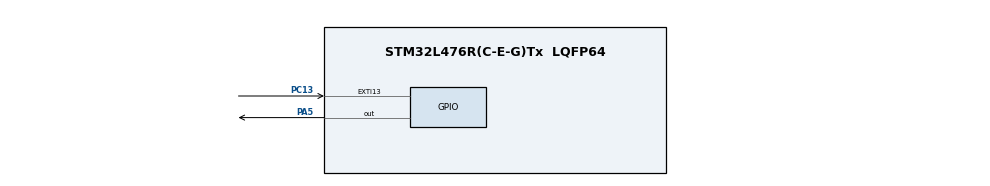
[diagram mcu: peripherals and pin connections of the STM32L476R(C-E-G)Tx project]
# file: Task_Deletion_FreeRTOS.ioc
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FREERTOS.Tasks01=defaultTask,24,128,StartDefaultTask,Default,NULL,Dynamic,NULL,NULL
Mcu.Family=STM32L4
Mcu.Name=STM32L476R(C-E-G)Tx
Mcu.Package=LQFP64
NVIC.EXTI15_10_IRQn=true\:5\:0\:false\:true\:true\:1\:true\:true\:true\:true
NVIC.PriorityGroup=NVIC_PRIORITYGROUP_4
PA5.Signal=GPIO_Output
PC13.Signal=GPXTI13
ProjectManager.HeapSize=0x200
ProjectManager.StackSize=0x400
ProjectManager.TargetToolchain=STM32CubeIDE
RCC.HSE_VALUE=8000000
RCC.HSI_VALUE=16000000
RCC.LSE_VALUE=32768
RCC.MSI_VALUE=4000000
RCC.VCOOutputFreq_Value=32000000
VP_FREERTOS_VS_CMSIS_V2.Mode=CMSIS_V2
board=custom

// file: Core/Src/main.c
/* USER CODE BEGIN Header */
/**
  ******************************************************************************
  * @file           : main.c
  * @brief          : Main program body
  ******************************************************************************
  * @attention
  *
  * Copyright (c) 2026 STMicroelectronics.
  * All rights reserved.
  *
  * This software is licensed under terms that can be found in the LICENSE file
  * in the root directory of this software component.
  * If no LICENSE file comes with this software, it is provided AS-IS.
  *
  ******************************************************************************
  */
/* USER CODE END Header */
#include "main.h"
#include "cmsis_os.h"

/* USER CODE BEGIN Includes */
#include <stdio.h>
#include "task.h"

/* USER CODE END Includes */

/* Definitions for defaultTask */

/* USER CODE BEGIN PV */
xTaskHandle Task1_Handle;
xTaskHandle Task2_Handle;
/* USER CODE END PV */

void SystemClock_Config(void);
static void MX_GPIO_Init(void);
void StartDefaultTask(void *argument);

static void MX_NVIC_Init(void);
/* USER CODE BEGIN PFP */
void Task1(void *argument);
void Task2(void *argument);

/* USER CODE END PFP */

int main(void)
{

  /* MCU Configuration--------------------------------------------------------*/

  /* Reset of all peripherals, Initializes the Flash interface and the Systick. */
  HAL_Init();

  /* Configure the system clock */
  SystemClock_Config();

  /* Initialize all configured peripherals */
  MX_GPIO_Init();

  /* Initialize interrupts */
  MX_NVIC_Init();

  /* Init scheduler */
  osKernelInitialize();

  /* Create the thread(s) */
  /* creation of defaultTask */
//  defaultTaskHandle = osThreadNew(StartDefaultTask, NULL, &defaultTask_attributes);

  xTaskCreate(Task2,"Task2",128,NULL,2,&Task1_Handle);
  xTaskCreate(Task1,"Task1",128,NULL,1,&Task2_Handle);

  /* Start scheduler */
//  osKernelStart();
  vTaskStartScheduler();
  /* We should never get here as control is now taken by the scheduler */

  /* Infinite loop */
  while (1)
  {

  }
}

void SystemClock_Config(void)
{
  RCC_OscInitTypeDef RCC_OscInitStruct = {0};
  RCC_ClkInitTypeDef RCC_ClkInitStruct = {0};

  /** Configure the main internal regulator output voltage
  */
  if (HAL_PWREx_ControlVoltageScaling(PWR_REGULATOR_VOLTAGE_SCALE1) != HAL_OK)
  {
    Error_Handler();
  }

  /** Initializes the RCC Oscillators according to the specified parameters
  * in the RCC_OscInitTypeDef structure.
  */
  RCC_OscInitStruct.OscillatorType = RCC_OSCILLATORTYPE_MSI;
  RCC_OscInitStruct.MSIState = RCC_MSI_ON;
  RCC_OscInitStruct.MSICalibrationValue = 0;
  RCC_OscInitStruct.MSIClockRange = RCC_MSIRANGE_6;
  RCC_OscInitStruct.PLL.PLLState = RCC_PLL_NONE;
  if (HAL_RCC_OscConfig(&RCC_OscInitStruct) != HAL_OK)
  {
    Error_Handler();
  }

  /** Initializes the CPU, AHB and APB buses clocks
  */
  RCC_ClkInitStruct.ClockType = RCC_CLOCKTYPE_HCLK|RCC_CLOCKTYPE_SYSCLK
                              |RCC_CLOCKTYPE_PCLK1|RCC_CLOCKTYPE_PCLK2;
  RCC_ClkInitStruct.SYSCLKSource = RCC_SYSCLKSOURCE_MSI;
  RCC_ClkInitStruct.AHBCLKDivider = RCC_SYSCLK_DIV1;
  RCC_ClkInitStruct.APB1CLKDivider = RCC_HCLK_DIV1;
  RCC_ClkInitStruct.APB2CLKDivider = RCC_HCLK_DIV1;

  if (HAL_RCC_ClockConfig(&RCC_ClkInitStruct, FLASH_LATENCY_0) != HAL_OK)
  {
    Error_Handler();
  }
}

/**
  * @brief NVIC Configuration.
  * @retval None
  */
static void MX_NVIC_Init(void)
{
  /* EXTI15_10_IRQn interrupt configuration */
  HAL_NVIC_SetPriority(EXTI15_10_IRQn, 5, 0);
  HAL_NVIC_EnableIRQ(EXTI15_10_IRQn);
}

static void MX_GPIO_Init(void)
{
  GPIO_InitTypeDef GPIO_InitStruct = {0};

  /* GPIO Ports Clock Enable */
  __HAL_RCC_GPIOC_CLK_ENABLE();
  __HAL_RCC_GPIOA_CLK_ENABLE();

  /*Configure GPIO pin Output Level */
  HAL_GPIO_WritePin(GPIOA, GPIO_PIN_5, GPIO_PIN_RESET);

  /*Configure GPIO pin : PC13 */
  GPIO_InitStruct.Pin = GPIO_PIN_13;
  GPIO_InitStruct.Mode = GPIO_MODE_IT_RISING;
  GPIO_InitStruct.Pull = GPIO_NOPULL;
  HAL_GPIO_Init(GPIOC, &GPIO_InitStruct);

  /*Configure GPIO pin : PA5 */
  GPIO_InitStruct.Pin = GPIO_PIN_5;
  GPIO_InitStruct.Mode = GPIO_MODE_OUTPUT_PP;
  GPIO_InitStruct.Pull = GPIO_NOPULL;
  GPIO_InitStruct.Speed = GPIO_SPEED_FREQ_LOW;
  HAL_GPIO_Init(GPIOA, &GPIO_InitStruct);

}

/* USER CODE BEGIN 4 */
void Task1(void *argument)
{
	while(1)
	{
		printf("i am task1\n");
		vTaskDelay(100);
	}
}

void Task2(void *argument)
{
	while(1)
	{
		printf("i am task2\n");
		vTaskDelay(10);
	}
}
//void Led_Blink_Task(void *argument)
//{
//    uint32_t val;
//
//    static uint8_t count = 0;
//
//
//    while(1)
//    {
//        if(xTaskNotifyWait(0, 0, &val, portMAX_DELAY) == pdTRUE)
//        {
////        	vTaskDelay(pdMS_TO_TICKS(50));
//        	HAL_GPIO_TogglePin(GPIOA, GPIO_PIN_5);
//
//        	count++;
//        }
//
//        if(++count == 5)
//        {
//            vTaskDelete(NULL);
//        }
//    }
//}
//
//void HAL_GPIO_EXTI_Callback(uint16_t GPIO_Pin)
//{
//    static TickType_t lastInterruptTime = 0;
//    TickType_t currentTime = xTaskGetTickCountFromISR();
//
//    if(GPIO_Pin == GPIO_PIN_13)
//    {
//        if((currentTime - lastInterruptTime) > pdMS_TO_TICKS(200))
//        {
//            BaseType_t xHigherPriorityTaskWoken = pdFALSE;
//
//            xTaskNotifyFromISR(
//                Led_Task_Handle,
//                1,
//                eSetValueWithOverwrite,
//                &xHigherPriorityTaskWoken
//            );
//
//            portYIELD_FROM_ISR(xHigherPriorityTaskWoken);
//
//            lastInterruptTime = currentTime;
//        }
//    }
//}
/* USER CODE END 4 */

//void StartDefaultTask(void *argument)
//{
//  /* USER CODE BEGIN 5 */
////  /* Infinite loop */
////  for(;;)
////  {
////    osDelay(1);
////  }
//  /* USER CODE END 5 */
//}

void Error_Handler(void)
{
  __disable_irq();
  while (1)
  {
  }
}
